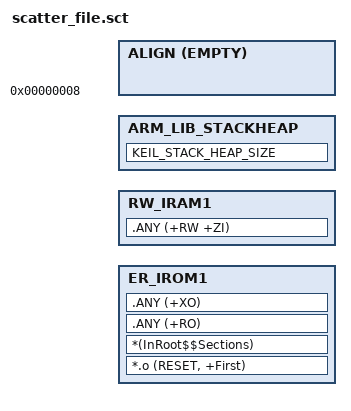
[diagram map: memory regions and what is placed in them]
; ***************************************************************
; *** Scatter-Loading Description File generated by Harmony 3 ***
; ***************************************************************

LR_IROM1 ${IROM1_START} ${IROM1_SIZE}  {    ; load region size_region
   ER_IROM1 ${IROM1_START} ${IROM1_SIZE}  {  ; load address = execution address
    *.o (RESET, +First)
    *(InRoot$$Sections)
    .ANY (+RO)
    .ANY (+XO)
   }
   RW_IRAM1 ${IRAM1_START} ${IRAM1_SIZE} - ${KEIL_STACK_HEAP_SIZE}  ; Entire RAM minus the stack and heap block
   {
     .ANY (+RW +ZI)
   }

   ARM_LIB_STACKHEAP ${IRAM1_START} + ${IRAM1_SIZE} - ${KEIL_STACK_HEAP_SIZE} ALIGN 8 EMPTY  ${KEIL_STACK_HEAP_SIZE} ; Stack heap block
   {

   }

}
